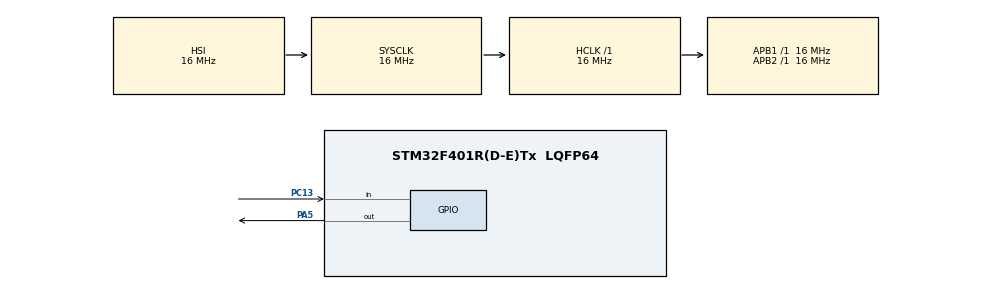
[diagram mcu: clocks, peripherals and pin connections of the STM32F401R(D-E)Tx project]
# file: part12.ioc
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Mcu.Family=STM32F4
Mcu.Name=STM32F401R(D-E)Tx
Mcu.Package=LQFP64
NVIC.PriorityGroup=NVIC_PRIORITYGROUP_4
PA5.Signal=GPIO_Output
PC13-ANTI_TAMP.GPIO_PuPd=GPIO_PULLUP
PC13-ANTI_TAMP.Signal=GPIO_Input
ProjectManager.HeapSize=0x200
ProjectManager.StackSize=0x400
ProjectManager.TargetToolchain=STM32CubeIDE
RCC.AHBFreq_Value=16000000
RCC.APB1Freq_Value=16000000
RCC.APB2Freq_Value=16000000
RCC.CortexFreq_Value=16000000
RCC.HSE_VALUE=25000000
RCC.HSI_VALUE=16000000
RCC.LSE_VALUE=32768
RCC.SYSCLKFreq_VALUE=16000000
RCC.VCOOutputFreq_Value=192000000
board=custom

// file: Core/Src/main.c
/* USER CODE BEGIN Header */
/**
  ******************************************************************************
  * @file           : main.c
  * @brief          : Main program body
  ******************************************************************************
  * @attention
  *
  * Copyright (c) 2025 STMicroelectronics.
  * All rights reserved.
  *
  * This software is licensed under terms that can be found in the LICENSE file
  * in the root directory of this software component.
  * If no LICENSE file comes with this software, it is provided AS-IS.
  *
  ******************************************************************************
  */
/* USER CODE END Header */
#include "main.h"

void SystemClock_Config(void);
static void MX_GPIO_Init(void);

int main(void)
{

  /* MCU Configuration--------------------------------------------------------*/

  /* Reset of all peripherals, Initializes the Flash interface and the Systick. */
  HAL_Init();

  /* Configure the system clock */
  SystemClock_Config();

  /* Initialize all configured peripherals */
  MX_GPIO_Init();

  /* Infinite loop */
  while (1)
  {

    /* USER CODE BEGIN 3 */
	  int C_input = LL_GPIO_ReadReg(GPIOC, IDR);
	  int push_status = (C_input >> 13) & 0x1;
	  if(push_status == 1){
	               LL_GPIO_WriteReg(GPIOA, ODR, (LL_GPIO_ReadReg(GPIOA, ODR) & ~(0x20)));
	           } else{
	        	   LL_GPIO_WriteReg(GPIOA, ODR, (LL_GPIO_ReadReg(GPIOA, ODR) | (0x20)));
	           }
  }
  /* USER CODE END 3 */
}

void SystemClock_Config(void)
{
  RCC_OscInitTypeDef RCC_OscInitStruct = {0};
  RCC_ClkInitTypeDef RCC_ClkInitStruct = {0};

  /** Configure the main internal regulator output voltage
  */
  __HAL_RCC_PWR_CLK_ENABLE();
  __HAL_PWR_VOLTAGESCALING_CONFIG(PWR_REGULATOR_VOLTAGE_SCALE2);

  /** Initializes the RCC Oscillators according to the specified parameters
  * in the RCC_OscInitTypeDef structure.
  */
  RCC_OscInitStruct.OscillatorType = RCC_OSCILLATORTYPE_HSI;
  RCC_OscInitStruct.HSIState = RCC_HSI_ON;
  RCC_OscInitStruct.HSICalibrationValue = RCC_HSICALIBRATION_DEFAULT;
  RCC_OscInitStruct.PLL.PLLState = RCC_PLL_NONE;
  if (HAL_RCC_OscConfig(&RCC_OscInitStruct) != HAL_OK)
  {
    Error_Handler();
  }

  /** Initializes the CPU, AHB and APB buses clocks
  */
  RCC_ClkInitStruct.ClockType = RCC_CLOCKTYPE_HCLK|RCC_CLOCKTYPE_SYSCLK
                              |RCC_CLOCKTYPE_PCLK1|RCC_CLOCKTYPE_PCLK2;
  RCC_ClkInitStruct.SYSCLKSource = RCC_SYSCLKSOURCE_HSI;
  RCC_ClkInitStruct.AHBCLKDivider = RCC_SYSCLK_DIV1;
  RCC_ClkInitStruct.APB1CLKDivider = RCC_HCLK_DIV1;
  RCC_ClkInitStruct.APB2CLKDivider = RCC_HCLK_DIV1;

  if (HAL_RCC_ClockConfig(&RCC_ClkInitStruct, FLASH_LATENCY_0) != HAL_OK)
  {
    Error_Handler();
  }
}

static void MX_GPIO_Init(void)
{
  LL_GPIO_InitTypeDef GPIO_InitStruct = {0};

  /* GPIO Ports Clock Enable */
  LL_AHB1_GRP1_EnableClock(LL_AHB1_GRP1_PERIPH_GPIOC);
  LL_AHB1_GRP1_EnableClock(LL_AHB1_GRP1_PERIPH_GPIOA);

  /**/
  LL_GPIO_ResetOutputPin(GPIOA, LL_GPIO_PIN_5);

  /**/
  GPIO_InitStruct.Pin = LL_GPIO_PIN_13;
  GPIO_InitStruct.Mode = LL_GPIO_MODE_INPUT;
  GPIO_InitStruct.Pull = LL_GPIO_PULL_UP;
  LL_GPIO_Init(GPIOC, &GPIO_InitStruct);

  /**/
  GPIO_InitStruct.Pin = LL_GPIO_PIN_5;
  GPIO_InitStruct.Mode = LL_GPIO_MODE_OUTPUT;
  GPIO_InitStruct.Speed = LL_GPIO_SPEED_FREQ_LOW;
  GPIO_InitStruct.OutputType = LL_GPIO_OUTPUT_PUSHPULL;
  GPIO_InitStruct.Pull = LL_GPIO_PULL_NO;
  LL_GPIO_Init(GPIOA, &GPIO_InitStruct);

}

void Error_Handler(void)
{
  __disable_irq();
  while (1)
  {
  }
}
